VERSION ""

NS_ :

BS_:

BU_: VCU JS
VAL_TABLE_ Button_Status 3 "Not Available" 2 "Error Indicator" 1 "Button Pressed" 0 "Button Not Pressed" ;
VAL_TABLE_ Axis_Status 3 "Not Available" 2 "Error Indicator" 1 "In Position" 0 "Not In Position" ;
VAL_TABLE_ DM1_Lamp 3 "Not Available" 2 "Reserved" 1 "Lamp On" 0 "Lamp Off" ;
VAL_TABLE_ DM1_Flash 3 "Unavailable / Do Not Flash" 2 "Reserved" 1 "Fast Flash" 0 "Slow Flash" ;

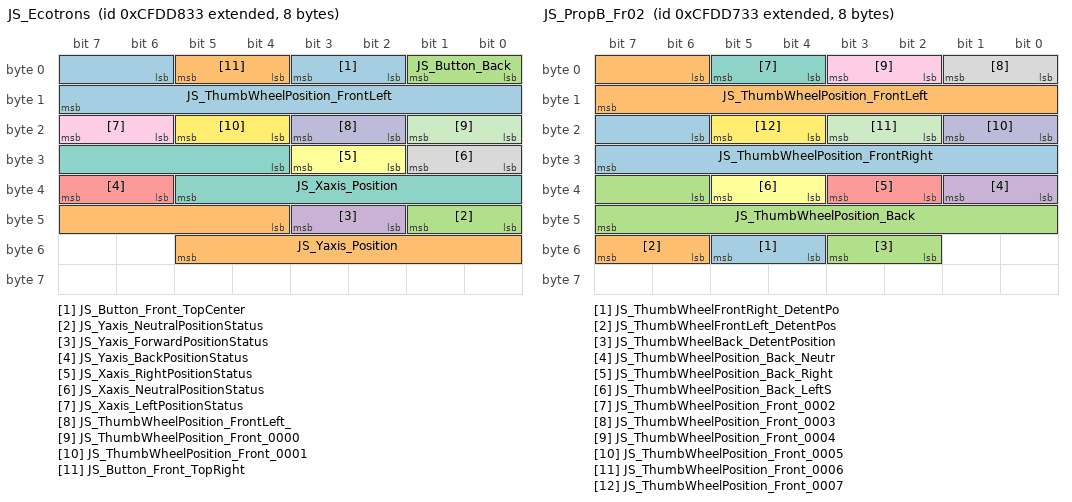
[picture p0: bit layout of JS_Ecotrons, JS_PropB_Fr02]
BO_ 2365446195 JS_Ecotrons: 8 Vector__XXX
 SG_ JS_Button_Front_TopCenter : 2|2@1+ (1,0) [0|3] "" Vector__XXX
 SG_ JS_Yaxis_Position : 44|10@1+ (0.1,0) [0|102.3] "%" Vector__XXX
 SG_ JS_Yaxis_NeutralPositionStatus : 40|2@1+ (1,0) [0|3] "" Vector__XXX
 SG_ JS_Yaxis_ForwardPositionStatus : 42|2@1+ (1,0) [0|3] "" Vector__XXX
 SG_ JS_Yaxis_BackPositionStatus : 38|2@1+ (1,0) [0|3] "" Vector__XXX
 SG_ JS_Xaxis_RightPositionStatus : 26|2@1+ (1,0) [0|3] "" Vector__XXX
 SG_ JS_Xaxis_Position : 28|10@1+ (0.1,0) [0|102.3] "%" Vector__XXX
 SG_ JS_Xaxis_NeutralPositionStatus : 24|2@1+ (1,0) [0|3] "" Vector__XXX
 SG_ JS_Xaxis_LeftPositionStatus : 22|2@1+ (1,0) [0|3] "" Vector__XXX
 SG_ JS_ThumbWheelPosition_FrontLeft_ : 18|2@1+ (1,0) [0|3] "" Vector__XXX
 SG_ JS_ThumbWheelPosition_Front_0000 : 16|2@1+ (1,0) [0|3] "" Vector__XXX
 SG_ JS_ThumbWheelPosition_Front_0001 : 20|2@1+ (1,0) [0|3] "" Vector__XXX
 SG_ JS_ThumbWheelPosition_FrontLeft : 6|10@1+ (0.1,0) [0|102.3] "%" Vector__XXX
 SG_ JS_Button_Front_TopRight : 4|2@1+ (1,0) [0|3] "" Vector__XXX
 SG_ JS_Button_Back : 0|2@1+ (1,0) [0|3] "" Vector__XXX

BO_ 2365445939 JS_PropB_Fr02: 8 JS
 SG_ JS_ThumbWheelFrontRight_DetentPo : 52|2@1+ (1,0) [0|3] "" Vector__XXX
 SG_ JS_ThumbWheelFrontLeft_DetentPos : 54|2@1+ (1,0) [0|3] "" Vector__XXX
 SG_ JS_ThumbWheelBack_DetentPosition : 50|2@1+ (1,0) [0|3] "" Vector__XXX
 SG_ JS_ThumbWheelPosition_Back_Neutr : 32|2@1+ (1,0) [0|3] "" Vector__XXX
 SG_ JS_ThumbWheelPosition_Back_Right : 34|2@1+ (1,0) [0|3] "" Vector__XXX
 SG_ JS_ThumbWheelPosition_Back_LeftS : 36|2@1+ (1,0) [0|3] "" Vector__XXX
 SG_ JS_ThumbWheelPosition_Front_0002 : 4|2@1+ (1,0) [0|3] "" Vector__XXX
 SG_ JS_ThumbWheelPosition_Front_0003 : 0|2@1+ (1,0) [0|3] "" Vector__XXX
 SG_ JS_ThumbWheelPosition_Front_0004 : 2|2@1+ (1,0) [0|3] "" Vector__XXX
 SG_ JS_ThumbWheelPosition_Front_0005 : 16|2@1+ (1,0) [0|3] "" Vector__XXX
 SG_ JS_ThumbWheelPosition_Front_0006 : 18|2@1+ (1,0) [0|3] "" Vector__XXX
 SG_ JS_ThumbWheelPosition_Front_0007 : 20|2@1+ (1,0) [0|3] "" Vector__XXX
 SG_ JS_ThumbWheelPosition_FrontRight : 22|10@1+ (0.1,0) [0|102.3] "%" Vector__XXX
 SG_ JS_ThumbWheelPosition_FrontLeft : 6|10@1+ (0.1,0) [0|102.3] "%" Vector__XXX
 SG_ JS_ThumbWheelPosition_Back : 38|10@1+ (0.1,0) [0|102.3] "%" Vector__XXX

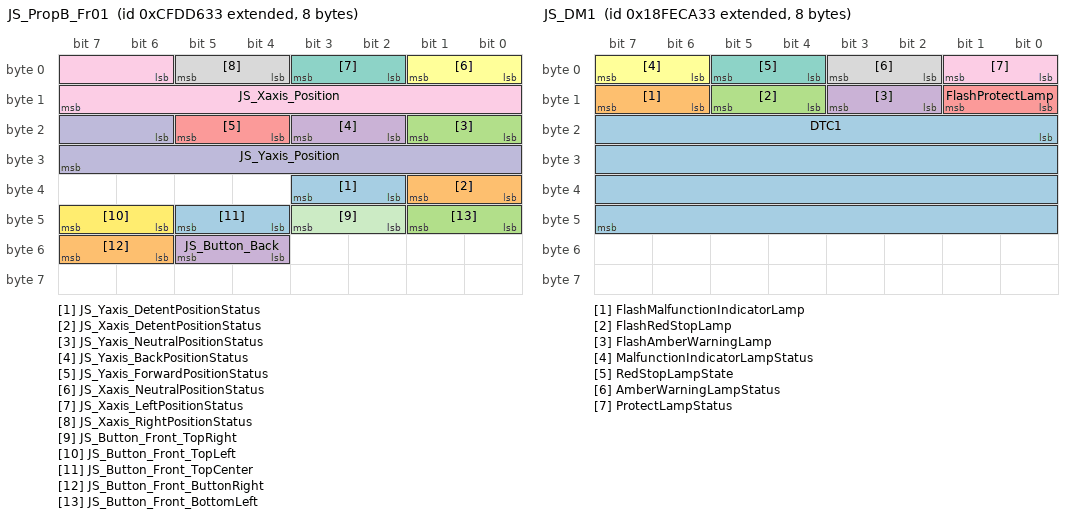
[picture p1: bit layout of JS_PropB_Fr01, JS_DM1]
BO_ 2365445683 JS_PropB_Fr01: 8 JS
 SG_ JS_Yaxis_DetentPositionStatus : 34|2@1+ (1,0) [0|3] "" Vector__XXX
 SG_ JS_Xaxis_DetentPositionStatus : 32|2@1+ (1,0) [0|3] "" Vector__XXX
 SG_ JS_Yaxis_NeutralPositionStatus : 16|2@1+ (1,0) [0|3] "" Vector__XXX
 SG_ JS_Yaxis_BackPositionStatus : 18|2@1+ (1,0) [0|3] "" Vector__XXX
 SG_ JS_Yaxis_ForwardPositionStatus : 20|2@1+ (1,0) [0|3] "" Vector__XXX
 SG_ JS_Xaxis_NeutralPositionStatus : 0|2@1+ (1,0) [0|3] "" Vector__XXX
 SG_ JS_Xaxis_LeftPositionStatus : 2|2@1+ (1,0) [0|3] "" Vector__XXX
 SG_ JS_Xaxis_RightPositionStatus : 4|2@1+ (1,0) [0|3] "" Vector__XXX
 SG_ JS_Xaxis_Position : 6|10@1+ (0.1,0) [0|102.3] "%" Vector__XXX
 SG_ JS_Yaxis_Position : 22|10@1+ (0.1,0) [0|102.3] "%" Vector__XXX
 SG_ JS_Button_Front_TopRight : 42|2@1+ (1,0) [0|3] "" Vector__XXX
 SG_ JS_Button_Front_TopLeft : 46|2@1+ (1,0) [0|3] "" Vector__XXX
 SG_ JS_Button_Front_TopCenter : 44|2@1+ (1,0) [0|3] "" Vector__XXX
 SG_ JS_Button_Front_ButtonRight : 54|2@1+ (1,0) [0|3] "" Vector__XXX
 SG_ JS_Button_Front_BottomLeft : 40|2@1+ (1,0) [0|3] "" Vector__XXX
 SG_ JS_Button_Back : 52|2@1+ (1,0) [0|3] "" Vector__XXX

BO_ 2566834739 JS_DM1: 8 JS
 SG_ DTC1 : 16|32@1+ (1,0) [0|4294967295] "" Vector__XXX
 SG_ FlashMalfunctionIndicatorLamp : 14|2@1+ (1,0) [0|3] "" Vector__XXX
 SG_ FlashRedStopLamp : 12|2@1+ (1,0) [0|3] "" Vector__XXX
 SG_ FlashAmberWarningLamp : 10|2@1+ (1,0) [0|3] "" Vector__XXX
 SG_ FlashProtectLamp : 8|2@1+ (1,0) [0|3] "" Vector__XXX
 SG_ MalfunctionIndicatorLampStatus : 6|2@1+ (1,0) [0|3] "" Vector__XXX
 SG_ RedStopLampState : 4|2@1+ (1,0) [0|3] "" Vector__XXX
 SG_ AmberWarningLampStatus : 2|2@1+ (1,0) [0|3] "" Vector__XXX
 SG_ ProtectLampStatus : 0|2@1+ (1,0) [0|3] "" Vector__XXX

BO_ 2565799731 JS_ACL: 8 JS

CM_ BU_ JS "Joystick";
BA_DEF_ BU_  "NmStationAddress" HEX 0 0;
BA_DEF_ BO_  "GenMsgCycleTime" INT 0 0;
BA_DEF_ BO_  "GenMsgSendType" ENUM  "Cyclic","not_used","not_used","not_used","not_used","Cyclic","not_used","IfActive";
BA_DEF_ SG_  "SystemSignalLongSymbol" STRING ;
BA_DEF_DEF_  "NmStationAddress" 0;
BA_DEF_DEF_  "GenMsgCycleTime" 0;
BA_DEF_DEF_  "GenMsgSendType" "not_used";
BA_DEF_DEF_  "SystemSignalLongSymbol" "";
BA_ "NmStationAddress" BU_ VCU 97;
BA_ "NmStationAddress" BU_ JS 51;
BA_ "GenMsgCycleTime" BO_ 2365446195 50;
BA_ "GenMsgSendType" BO_ 2365446195 0;
BA_ "GenMsgSendType" BO_ 2365445939 0;
BA_ "GenMsgCycleTime" BO_ 2365445939 50;
BA_ "GenMsgSendType" BO_ 2365445683 0;
BA_ "GenMsgCycleTime" BO_ 2365445683 50;
BA_ "GenMsgSendType" BO_ 2566834739 0;
BA_ "GenMsgCycleTime" BO_ 2566834739 1000;
BA_ "GenMsgSendType" BO_ 2565799731 7;
BA_ "SystemSignalLongSymbol" SG_ 2365446195 JS_ThumbWheelPosition_FrontLeft_ "JS_ThumbWheelPosition_FrontLeft_TopStatus";
BA_ "SystemSignalLongSymbol" SG_ 2365446195 JS_ThumbWheelPosition_Front_0000 "JS_ThumbWheelPosition_FrontLeft_NeutralStatus";
BA_ "SystemSignalLongSymbol" SG_ 2365446195 JS_ThumbWheelPosition_Front_0001 "JS_ThumbWheelPosition_FrontLeft_DownStatus";
BA_ "SystemSignalLongSymbol" SG_ 2365445939 JS_ThumbWheelFrontRight_DetentPo "JS_ThumbWheelFrontRight_DetentPositionStatus";
BA_ "SystemSignalLongSymbol" SG_ 2365445939 JS_ThumbWheelFrontLeft_DetentPos "JS_ThumbWheelFrontLeft_DetentPositionStatus";
BA_ "SystemSignalLongSymbol" SG_ 2365445939 JS_ThumbWheelBack_DetentPosition "JS_ThumbWheelBack_DetentPositionStatus";
BA_ "SystemSignalLongSymbol" SG_ 2365445939 JS_ThumbWheelPosition_Back_Neutr "JS_ThumbWheelPosition_Back_NeutralStatus";
BA_ "SystemSignalLongSymbol" SG_ 2365445939 JS_ThumbWheelPosition_Back_Right "JS_ThumbWheelPosition_Back_RightStatus";
BA_ "SystemSignalLongSymbol" SG_ 2365445939 JS_ThumbWheelPosition_Back_LeftS "JS_ThumbWheelPosition_Back_LeftStatus";
BA_ "SystemSignalLongSymbol" SG_ 2365445939 JS_ThumbWheelPosition_Front_0002 "JS_ThumbWheelPosition_FrontLeft_TopStatus";
BA_ "SystemSignalLongSymbol" SG_ 2365445939 JS_ThumbWheelPosition_Front_0003 "JS_ThumbWheelPosition_FrontLeft_NeutralStatus";
BA_ "SystemSignalLongSymbol" SG_ 2365445939 JS_ThumbWheelPosition_Front_0004 "JS_ThumbWheelPosition_FrontLeft_DownStatus";
BA_ "SystemSignalLongSymbol" SG_ 2365445939 JS_ThumbWheelPosition_Front_0005 "JS_ThumbWheelPosition_FrontRight_NeutralStatus";
BA_ "SystemSignalLongSymbol" SG_ 2365445939 JS_ThumbWheelPosition_Front_0006 "JS_ThumbWheelPosition_FrontRight_DownStatus";
BA_ "SystemSignalLongSymbol" SG_ 2365445939 JS_ThumbWheelPosition_Front_0007 "JS_ThumbWheelPosition_FrontRight_TopStatus";
VAL_ 2365446195 JS_Button_Front_TopCenter 3 "Not Available" 2 "Error Indicator" 1 "Button Pressed" 0 "Button Not Pressed" ;
VAL_ 2365446195 JS_Yaxis_NeutralPositionStatus 3 "Not Available" 2 "Error Indicator" 1 "In Position" 0 "Not In Position" ;
VAL_ 2365446195 JS_Yaxis_ForwardPositionStatus 3 "Not Available" 2 "Error Indicator" 1 "In Position" 0 "Not In Position" ;
VAL_ 2365446195 JS_Yaxis_BackPositionStatus 3 "Not Available" 2 "Error Indicator" 1 "In Position" 0 "Not In Position" ;
VAL_ 2365446195 JS_Xaxis_RightPositionStatus 3 "Not Available" 2 "Error Indicator" 1 "In Position" 0 "Not In Position" ;
VAL_ 2365446195 JS_Xaxis_NeutralPositionStatus 3 "Not Available" 2 "Error Indicator" 1 "In Position" 0 "Not In Position" ;
VAL_ 2365446195 JS_Xaxis_LeftPositionStatus 3 "Not Available" 2 "Error Indicator" 1 "In Position" 0 "Not In Position" ;
VAL_ 2365446195 JS_ThumbWheelPosition_FrontLeft_ 3 "Not Available" 2 "Error Indicator" 1 "In Position" 0 "Not In Position" ;
VAL_ 2365446195 JS_ThumbWheelPosition_Front_0000 3 "Not Available" 2 "Error Indicator" 1 "In Position" 0 "Not In Position" ;
VAL_ 2365446195 JS_ThumbWheelPosition_Front_0001 3 "Not Available" 2 "Error Indicator" 1 "In Position" 0 "Not In Position" ;
VAL_ 2365446195 JS_Button_Front_TopRight 3 "Not Available" 2 "Error Indicator" 1 "Button Pressed" 0 "Button Not Pressed" ;
VAL_ 2365446195 JS_Button_Back 3 "Not Available" 2 "Error Indicator" 1 "Button Pressed" 0 "Button Not Pressed" ;
VAL_ 2365445939 JS_ThumbWheelFrontRight_DetentPo 3 "Not Available" 2 "Error Indicator" 1 "In Position" 0 "Not In Position" ;
VAL_ 2365445939 JS_ThumbWheelFrontLeft_DetentPos 3 "Not Available" 2 "Error Indicator" 1 "In Position" 0 "Not In Position" ;
VAL_ 2365445939 JS_ThumbWheelBack_DetentPosition 3 "Not Available" 2 "Error Indicator" 1 "In Position" 0 "Not In Position" ;
VAL_ 2365445939 JS_ThumbWheelPosition_Back_Neutr 3 "Not Available" 2 "Error Indicator" 1 "In Position" 0 "Not In Position" ;
VAL_ 2365445939 JS_ThumbWheelPosition_Back_Right 3 "Not Available" 2 "Error Indicator" 1 "In Position" 0 "Not In Position" ;
VAL_ 2365445939 JS_ThumbWheelPosition_Back_LeftS 3 "Not Available" 2 "Error Indicator" 1 "In Position" 0 "Not In Position" ;
VAL_ 2365445939 JS_ThumbWheelPosition_Front_0002 3 "Not Available" 2 "Error Indicator" 1 "In Position" 0 "Not In Position" ;
VAL_ 2365445939 JS_ThumbWheelPosition_Front_0003 3 "Not Available" 2 "Error Indicator" 1 "In Position" 0 "Not In Position" ;
VAL_ 2365445939 JS_ThumbWheelPosition_Front_0004 3 "Not Available" 2 "Error Indicator" 1 "In Position" 0 "Not In Position" ;
VAL_ 2365445939 JS_ThumbWheelPosition_Front_0005 3 "Not Available" 2 "Error Indicator" 1 "In Position" 0 "Not In Position" ;
VAL_ 2365445939 JS_ThumbWheelPosition_Front_0006 3 "Not Available" 2 "Error Indicator" 1 "In Position" 0 "Not In Position" ;
VAL_ 2365445939 JS_ThumbWheelPosition_Front_0007 3 "Not Available" 2 "Error Indicator" 1 "In Position" 0 "Not In Position" ;
VAL_ 2365445683 JS_Yaxis_DetentPositionStatus 3 "Not Available" 2 "Error Indicator" 1 "In Position" 0 "Not In Position" ;
VAL_ 2365445683 JS_Xaxis_DetentPositionStatus 3 "Not Available" 2 "Error Indicator" 1 "In Position" 0 "Not In Position" ;
VAL_ 2365445683 JS_Yaxis_NeutralPositionStatus 3 "Not Available" 2 "Error Indicator" 1 "In Position" 0 "Not In Position" ;
VAL_ 2365445683 JS_Yaxis_BackPositionStatus 3 "Not Available" 2 "Error Indicator" 1 "In Position" 0 "Not In Position" ;
VAL_ 2365445683 JS_Yaxis_ForwardPositionStatus 3 "Not Available" 2 "Error Indicator" 1 "In Position" 0 "Not In Position" ;
VAL_ 2365445683 JS_Xaxis_NeutralPositionStatus 3 "Not Available" 2 "Error Indicator" 1 "In Position" 0 "Not In Position" ;
VAL_ 2365445683 JS_Xaxis_LeftPositionStatus 3 "Not Available" 2 "Error Indicator" 1 "In Position" 0 "Not In Position" ;
VAL_ 2365445683 JS_Xaxis_RightPositionStatus 3 "Not Available" 2 "Error Indicator" 1 "In Position" 0 "Not In Position" ;
VAL_ 2365445683 JS_Button_Front_TopRight 3 "Not Available" 2 "Error Indicator" 1 "Button Pressed" 0 "Button Not Pressed" ;
VAL_ 2365445683 JS_Button_Front_TopLeft 3 "Not Available" 2 "Error Indicator" 1 "Button Pressed" 0 "Button Not Pressed" ;
VAL_ 2365445683 JS_Button_Front_TopCenter 3 "Not Available" 2 "Error Indicator" 1 "Button Pressed" 0 "Button Not Pressed" ;
VAL_ 2365445683 JS_Button_Front_ButtonRight 3 "Not Available" 2 "Error Indicator" 1 "Button Pressed" 0 "Button Not Pressed" ;
VAL_ 2365445683 JS_Button_Front_BottomLeft 3 "Not Available" 2 "Error Indicator" 1 "Button Pressed" 0 "Button Not Pressed" ;
VAL_ 2365445683 JS_Button_Back 3 "Not Available" 2 "Error Indicator" 1 "Button Pressed" 0 "Button Not Pressed" ;
VAL_ 2566834739 FlashMalfunctionIndicatorLamp 3 "Unavailable / Do Not Flash" 2 "Reserved" 1 "Fast Flash" 0 "Slow Flash" ;
VAL_ 2566834739 FlashRedStopLamp 3 "Unavailable / Do Not Flash" 2 "Reserved" 1 "Fast Flash" 0 "Slow Flash" ;
VAL_ 2566834739 FlashAmberWarningLamp 3 "Unavailable / Do Not Flash" 2 "Reserved" 1 "Fast Flash" 0 "Slow Flash" ;
VAL_ 2566834739 FlashProtectLamp 3 "Unavailable / Do Not Flash" 2 "Reserved" 1 "Fast Flash" 0 "Slow Flash" ;
VAL_ 2566834739 MalfunctionIndicatorLampStatus 3 "Not Available" 2 "Reserved" 1 "Lamp On" 0 "Lamp Off" ;
VAL_ 2566834739 RedStopLampState 3 "Not Available" 2 "Reserved" 1 "Lamp On" 0 "Lamp Off" ;
VAL_ 2566834739 AmberWarningLampStatus 3 "Not Available" 2 "Reserved" 1 "Lamp On" 0 "Lamp Off" ;
VAL_ 2566834739 ProtectLampStatus 3 "Not Available" 2 "Reserved" 1 "Lamp On" 0 "Lamp Off" ;
